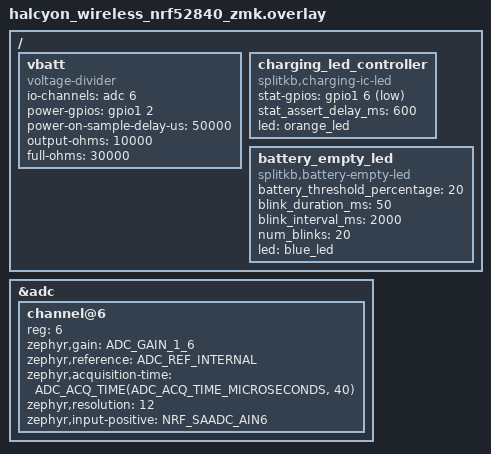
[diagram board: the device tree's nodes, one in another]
/*
 * Copyright (c) 2026 Splitkb.com
 *
 * SPDX-License-Identifier: MIT
 */
 
/ {
    vbatt: vbatt {
        compatible = "voltage-divider";
        io-channels = <&adc 6>; // P0.30
        power-gpios = <&gpio1 2 GPIO_ACTIVE_HIGH>;
        power-on-sample-delay-us = <50000>;
        output-ohms = <10000>;
        full-ohms = <30000>;
    };

    charging_led_controller {
        compatible = "splitkb,charging-ic-led";
        status = "okay";
        stat-gpios = <&gpio1 6 (GPIO_ACTIVE_LOW | GPIO_PULL_UP)>;
        stat_assert_delay_ms = <600>;
        led = <&orange_led>; 
    };

    battery_empty_led: battery_empty_led {
        compatible = "splitkb,battery-empty-led";
        status = "okay";
        battery_threshold_percentage = <20>;
        blink_duration_ms = <50>;
        blink_interval_ms = <2000>;
        num_blinks = <20>;
        led = <&blue_led>;
    };
};

&adc {
    #address-cells = <1>;
    #size-cells = <0>;
    status = "okay";

    channel@6 {
        reg = <6>;
        zephyr,gain = "ADC_GAIN_1_6";
        zephyr,reference = "ADC_REF_INTERNAL";
        zephyr,acquisition-time = <ADC_ACQ_TIME(ADC_ACQ_TIME_MICROSECONDS, 40)>;
        zephyr,resolution = <12>;
        zephyr,input-positive = <NRF_SAADC_AIN6>;
    };
};
